# PIC16F1782 register map
Vendor: Microchip
Registers are 8-bit, read-write, reset 0x0 unless marked. A register's access mark holds for its fields unless they carry their own. Addresses are absolute, and some are shared; only a register's first bit layout is shown; [hi:lo] are bit positions; {n}, {i} and the like mark numbered series.

## SFR
0x00 INDF0 reset not defined — (power-on value xxxxxxxx)
0x01 INDF1 reset not defined — (power-on value xxxxxxxx)
0x02 PCL
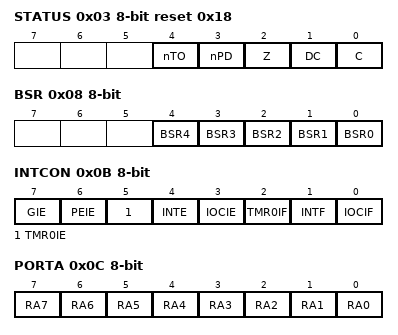
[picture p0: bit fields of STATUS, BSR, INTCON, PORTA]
0x03 STATUS reset 0x18
  [4] nTO ro, [3] nPD ro, [2] Z, [1] DC, [0] C
0x04 FSR0L
0x05 FSR0H
0x06 FSR1L
0x07 FSR1H
0x08 BSR
  [n] BSR{n} (n=0..4)
0x09 WREG
  [7:0] WREG0
0x0A PCLATH
  [6:0] PCLATH
0x0B INTCON
  [7] GIE, [6] PEIE, [5] TMR0IE, [4] INTE, [3] IOCIE, [2] TMR0IF, [1] INTF, [0] IOCIF ro
0x0C PORTA reset not defined — (power-on value xxxxxxxx)
  [n] RA{n} (n=0..7)
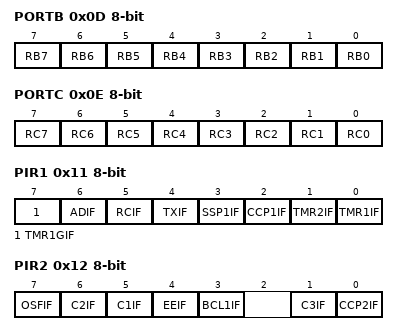
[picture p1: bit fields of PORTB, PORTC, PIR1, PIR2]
0x0D PORTB reset not defined — (power-on value xxxxxxxx)
  [n] RB{n} (n=0..7)
0x0E PORTC reset not defined — (power-on value xxxxxxxx)
  [n] RC{n} (n=0..7)
0x10 PORTE ro reset not defined — (power-on value ----x---)
  [3] RE3
0x11 PIR1
  [7] TMR1GIF — Timer1 Gate Interrupt Flag bit
  [6] ADIF — A/D Converter Interrupt Flag bit
  [5] RCIF ro — EUSART Receive Interrupt Flag bit
  [4] TXIF ro — EUSART Transmit Interrupt Flag bit
  [3] SSP1IF — Master Synchronous Serial Port (MSSP) Interrupt Flag bit
  [2] CCP1IF — CCP1 Interrupt Flag bit
  [1] TMR2IF — TMR2 to PR2 Match Interrupt Flag bit
  [0] TMR1IF — TMR1 Overflow Interrupt Flag bit
0x12 PIR2
  [7] OSFIF, [6] C2IF, [5] C1IF, [4] EEIF, [3] BCL1IF, [1] C3IF, [0] CCP2IF
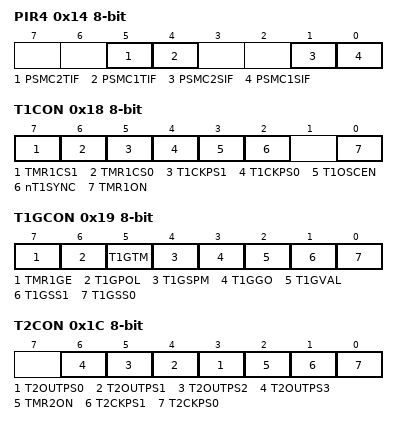
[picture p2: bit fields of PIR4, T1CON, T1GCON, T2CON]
0x14 PIR4
  [5] PSMC2TIF, [4] PSMC1TIF, [1] PSMC2SIF, [0] PSMC1SIF
0x15 TMR0 reset not defined — (power-on value xxxxxxxx)
0x16 TMR1L reset not defined — (power-on value xxxxxxxx)
0x17 TMR1H reset not defined — (power-on value xxxxxxxx)
0x18 T1CON
  [7] TMR1CS1, [6] TMR1CS0, [5] T1CKPS1, [4] T1CKPS0, [3] T1OSCEN, [2] nT1SYNC, [0] TMR1ON
0x19 T1GCON reset not defined — (power-on value 00000x00)
  [7] TMR1GE, [6] T1GPOL, [5] T1GTM, [4] T1GSPM, [3] T1GGO, [2] T1GVAL ro, [1] T1GSS1, [0] T1GSS0
0x1A TMR2
0x1B PR2 reset 0xFF
0x1C T2CON
  [n+3] T2OUTPS{n} (n=0..3), [2] TMR2ON, [1] T2CKPS1, [0] T2CKPS0
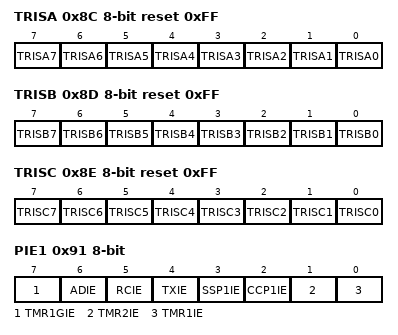
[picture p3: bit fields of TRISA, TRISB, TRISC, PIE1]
0x8C TRISA reset 0xFF — PORTA Data Direction Control Register
  [n] TRISA{n} (n=0..7)
0x8D TRISB reset 0xFF
  [n] TRISB{n} (n=0..7)
0x8E TRISC reset 0xFF — PORTB Data Direction Control Register
  [n] TRISC{n} (n=0..7)
0x90 TRISE reset 0x8
  [3] TRISE3
0x91 PIE1 — Peripheral Interrupt Enable Register 1
  [7] TMR1GIE — Timer1 Gate Interrupt Enable bit
  [6] ADIE — A/D Converter Interrupt Enable bit
  [5] RCIE — EUSART Receive Interrupt Enable bit
  [4] TXIE — EUSART Transmit Interrupt Enable bit
  [3] SSP1IE — Master Synchronous Serial Port (MSSP) Interrupt Enable bit
  [2] CCP1IE — CCP1 Interrupt Enable bit
  [1] TMR2IE — TMR2 to PR2 Match Interrupt Enable bit
  [0] TMR1IE — TMR1 Overflow Interrupt Enable bit
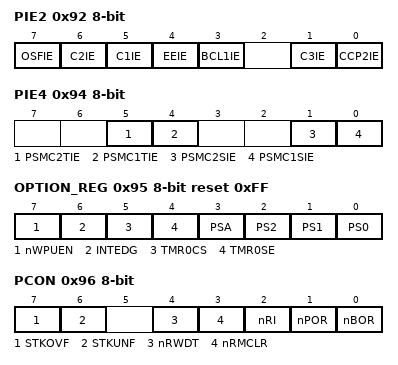
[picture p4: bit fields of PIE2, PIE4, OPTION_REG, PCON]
0x92 PIE2 — Peripheral Interrupt Enable Register 2
  [7] OSFIE — CCP2 Interrupt Enable bit
  [6] C2IE — Comparator C2 Interrupt Enable bit
  [5] C1IE — Comparator C1 Interrupt Enable bit
  [4] EEIE — EEPROM Write Completion Interrupt Enable bit
  [3] BCL1IE — MSSP Bus Collision Interrupt Interrupt Enable bit
  [1] C3IE
  [0] CCP2IE
0x94 PIE4
  [5] PSMC2TIE, [4] PSMC1TIE, [1] PSMC2SIE, [0] PSMC1SIE
0x95 OPTION_REG reset 0xFF — Option Register
  [7] nWPUEN — Weak Pull-up Enable bit
  [6] INTEDG — Interrupt Edge Select bit
  [5] TMR0CS — TMR0 Clock Source Select bit
  [4] TMR0SE — TMR0 Source Edge Select bit
  [3] PSA — Prescaler Active bit
  [2] PS2 — Prescaler Rate Select bits
  [1] PS1 — Prescaler Rate Select bits
  [0] PS0 — Prescaler Rate Select bits
0x96 PCON reset not defined — Power Control Register (power-on value 00-111qq)
  [7] STKOVF — Stack Overflow Flag bit
  [6] STKUNF — Stack Underflow Flag bit
  [4] nRWDT
  [3] nRMCLR — MCLR Reset Flag bit
  [2] nRI — RESET Instruction Flag bit
  [1] nPOR — Power-on Reset Status bit
  [0] nBOR — Brown-out Reset Status bit
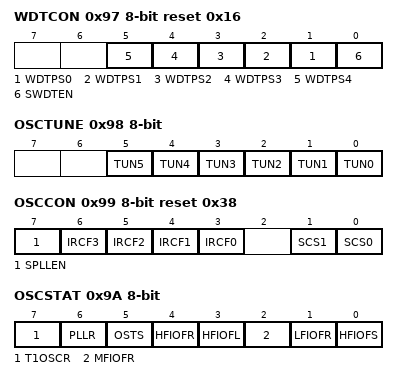
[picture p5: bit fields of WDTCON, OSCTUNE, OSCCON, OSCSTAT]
0x97 WDTCON reset 0x16 — Watchdog Timer Control Register
  [n+1] WDTPS{n} (n=0..4) — Watchdog Timer Period Select bits
  [0] SWDTEN — Software Enable/Disable for Watch Dog Timer bit
0x98 OSCTUNE — Oscillator Tuning Register
  [n] TUN{n} (n=0..5) — Frequency Tuning bits
0x99 OSCCON reset 0x38 — Oscillator Control Register
  [7] SPLLEN — Software PLL Enable bit
  [n+3] IRCF{n} (n=0..3) — Internal Oscillator Frequency Select bits
  [1] SCS1 — System clock select bit
  [0] SCS0 — System clock select bit
0x9A OSCSTAT ro reset not defined — Oscillator Status Register (power-on value 10q00q00)
  [7] T1OSCR — Timer1 Oscillator Ready bit
  [6] PLLR — 4x PLL Ready bit
  [5] OSTS — Oscillator Start-up Time-out Status bit
  [4] HFIOFR — High Freqency Internal Oscillator Ready bit
  [3] HFIOFL — High Freqency Internal Oscillator Status Locked bit
  [2] MFIOFR — Medium Freqency Internal Oscillator Ready bit
  [1] LFIOFR — Low Freqency Internal Oscillator Ready bit
  [0] HFIOFS — Low Freqency Internal Oscillator Ready bit
0x9B ADRESL reset not defined — A/D Result Register LSB (power-on value xxxxxxxx)
0x9C ADRESH reset not defined — A/D Result Register MSB (power-on value xxxxxxxx)
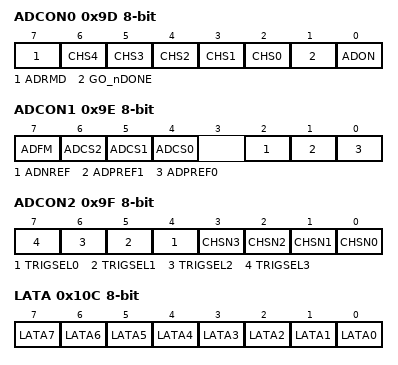
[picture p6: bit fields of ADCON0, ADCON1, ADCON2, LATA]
0x9D ADCON0 — Analog-to-Digital Control Register 0
  [7] ADRMD
  [n+2] CHS{n} (n=0..4) — Analog Channel Select bits
  [1] GO_nDONE — A/D Conversion Status bit
  [0] ADON — A/D Module Enable bit
0x9E ADCON1 — Analog-to-Digital Control Register 1
  [7] ADFM — A/D Result Format Select bit
  [6] ADCS2 — A/D Conversion Clock Select bits
  [5] ADCS1 — A/D Conversion Clock Select bits
  [4] ADCS0 — A/D Conversion Clock Select bits
  [2] ADNREF — A/D Negative Voltage Reference Configuration
  [1] ADPREF1 — A/D Positive Voltage Reference Configuration
  [0] ADPREF0 — A/D Positive Voltage Reference Configuration
0x9F ADCON2
  [n+4] TRIGSEL{n} (n=0..3), [n] CHSN{n} (n=0..3)
0x10C LATA reset not defined — (power-on value xxxxxxxx)
  [n] LATA{n} (n=0..7)
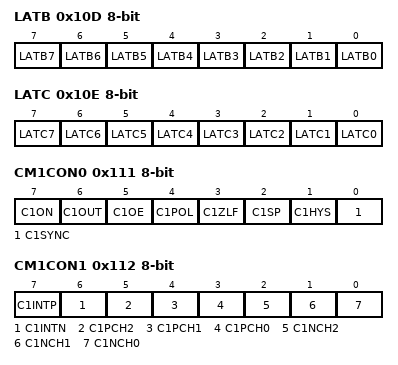
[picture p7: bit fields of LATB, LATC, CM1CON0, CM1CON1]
0x10D LATB reset not defined — (power-on value xxxxxxxx)
  [n] LATB{n} (n=0..7)
0x10E LATC reset not defined — (power-on value xxxxxxxx)
  [n] LATC{n} (n=0..7)
0x111 CM1CON0 reset not defined — (power-on value 0000x100)
  [7] C1ON — Comparator Enable bit
  [6] C1OUT ro — Comparator Output bit
  [5] C1OE — Comparator Output Enable bit
  [4] C1POL — Comparator Output Polarity Select bit
  [3] C1ZLF
  [2] C1SP — Comparator Speed/Power Select bit
  [1] C1HYS — Comparator Hysteresis Enable bit
  [0] C1SYNC — Comparator Output Synchronous Mode bit
0x112 CM1CON1
  [7] C1INTP — Comparator Interrupt on Positive going edge Enable bits
  [6] C1INTN — Comparator Interrupt on Negative going edge Enable bits
  [5] C1PCH2
  [4] C1PCH1
  [3] C1PCH0
  [2] C1NCH2
  [1] C1NCH1 — Comparator Negative Input Channel Select bits
  [0] C1NCH0 — Comparator Negative Input Channel Select bits
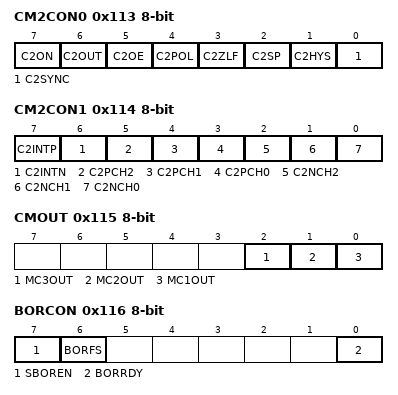
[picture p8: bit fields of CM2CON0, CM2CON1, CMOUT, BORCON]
0x113 CM2CON0 reset not defined — (power-on value 0000x100)
  [7] C2ON, [6] C2OUT ro, [5] C2OE, [4] C2POL, [3] C2ZLF, [2] C2SP, [1] C2HYS, [0] C2SYNC
0x114 CM2CON1
  [7] C2INTP — Comparator Interrupt on Positive going edge Enable bits
  [6] C2INTN — Comparator Interrupt on Negative going edge Enable bits
  [5] C2PCH2
  [4] C2PCH1
  [3] C2PCH0
  [2] C2NCH2
  [1] C2NCH1 — Comparator Negative Input Channel Select bits
  [0] C2NCH0 — Comparator Negative Input Channel Select bits
0x115 CMOUT ro — Comparator Output Register
  [2] MC3OUT, [1] MC2OUT, [0] MC1OUT
0x116 BORCON reset not defined — Brown-out Reset Control Register (power-on value 10-----q)
  [7] SBOREN — Software Brown Out Reset Enable bit
  [6] BORFS
  [0] BORRDY ro — Brown-out Reset Circuit Ready Status bit
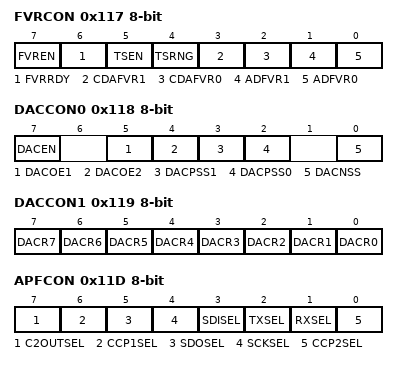
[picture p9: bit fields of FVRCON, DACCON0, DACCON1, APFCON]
0x117 FVRCON reset not defined — Fixed Voltage Reference Control Register (power-on value 0q000000)
  [7] FVREN — Fixed Voltage Reference Enable
  [6] FVRRDY ro — Fixed Voltage Reference Ready Flag
  [5] TSEN
  [4] TSRNG
  [3] CDAFVR1 — Comparator and D/A Converter Fixed Voltage Reference Selection
  [2] CDAFVR0 — Comparator and D/A Converter Fixed Voltage Reference Selection
  [1] ADFVR1 — A/D Converter Fixed Voltage Reference Selection
  [0] ADFVR0 — A/D Converter Fixed Voltage Reference Selection
0x118 DACCON0 reset not defined — Voltage Reference Control Register 0 (power-on value 0-0x00-0)
  [7] DACEN — DAC 1 Enable bit
  [5] DACOE1 — DAC1 Voltage Output Enable bit
  [4] DACOE2
  [3] DACPSS1 — DAC1 Positive Source Select bits
  [2] DACPSS0 — DAC1 Positive Source Select bits
  [0] DACNSS — DAC1 Negative Source Select bits
0x119 DACCON1 — Voltage Reference Control Register 1
  [7] DACR7
  [6] DACR6
  [5] DACR5
  [n] DACR{n} (n=0..4) — DAC1 Voltage Output Select bits
0x11D APFCON — Alternate Pin Function Control Register
  [7] C2OUTSEL, [6] CCP1SEL, [5] SDOSEL, [4] SCKSEL, [3] SDISEL, [2] TXSEL, [1] RXSEL, [0] CCP2SEL
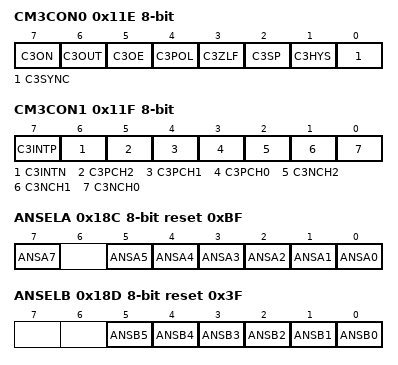
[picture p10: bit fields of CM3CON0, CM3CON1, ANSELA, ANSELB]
0x11E CM3CON0 reset not defined — (power-on value 0000x100)
  [7] C3ON, [6] C3OUT, [5] C3OE, [4] C3POL, [3] C3ZLF, [2] C3SP, [1] C3HYS, [0] C3SYNC
0x11F CM3CON1
  [7] C3INTP, [6] C3INTN, [5] C3PCH2, [4] C3PCH1, [3] C3PCH0, [2] C3NCH2, [1] C3NCH1, [0] C3NCH0
0x18C ANSELA reset 0xBF
  [7] ANSA7, [n] ANSA{n} (n=0..5)
0x18D ANSELB reset 0x3F
  [n] ANSB{n} (n=0..5)
0x191 EEADRL
0x192 EEADRH reset 0x80
  [6:0] EEADRH
0x193 EEDATL reset not defined — (power-on value xxxxxxxx)
0x194 EEDATH reset not defined — (power-on value --xxxxxx)
  [5:0] EEDATH
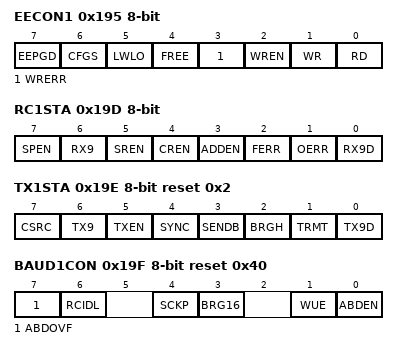
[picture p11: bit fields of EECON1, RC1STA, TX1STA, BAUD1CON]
0x195 EECON1 reset not defined — (power-on value 0000x000)
  [7] EEPGD — FLASH Program / Data EEPROM Memory Select bit
  [6] CFGS — FLASH Program / Data EEPROM or Configuration Select bit
  [5] LWLO — Load Write Latches Only bit
  [4] FREE — Program FLASH Erase Enable bit
  [3] WRERR — Sequence Error Flag bit
  [2] WREN — Program/Erase Enable bit
  [1] WR — Write Control bit (can only be set)
  [0] RD — Read Control bit (can only be set)
0x196 EECON2 wo
0x197 VREGCON reset 0x1
  [1] VREGPM
0x199 RC1REG ro
0x19A TX1REG
0x19B SP1BRGL
0x19C SP1BRGH
0x19D RC1STA
  [7] SPEN, [6] RX9, [5] SREN, [4] CREN, [3] ADDEN, [2] FERR ro, [1] OERR ro, [0] RX9D ro
0x19E TX1STA reset 0x2
  [7] CSRC, [6] TX9, [5] TXEN, [4] SYNC, [3] SENDB, [2] BRGH, [1] TRMT ro, [0] TX9D
0x19F BAUD1CON reset 0x40
  [7] ABDOVF ro, [6] RCIDL ro, [4] SCKP, [3] BRG16, [1] WUE, [0] ABDEN
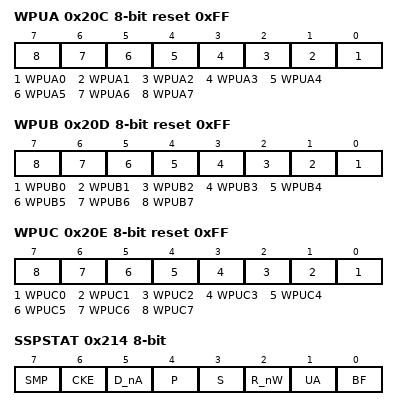
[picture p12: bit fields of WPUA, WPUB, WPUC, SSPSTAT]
0x20C WPUA reset 0xFF
  [n] WPUA{n} (n=0..7)
0x20D WPUB reset 0xFF
  [n] WPUB{n} (n=0..7)
0x20E WPUC reset 0xFF
  [n] WPUC{n} (n=0..7)
0x210 WPUE reset 0x8
  [3] WPUE3
0x211 SSPBUF reset not defined — (power-on value xxxxxxxx)
0x212 SSPADD
0x213 SSPMSK reset 0xFF
0x214 SSPSTAT
  [7] SMP, [6] CKE, [5] D_nA, [4] P, [3] S, [2] R_nW, [1] UA, [0] BF
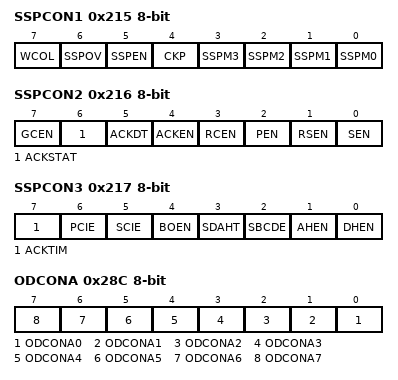
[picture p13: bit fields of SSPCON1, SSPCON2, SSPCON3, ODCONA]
0x215 SSPCON1
  [7] WCOL, [6] SSPOV, [5] SSPEN, [4] CKP, [n] SSPM{n} (n=0..3)
0x216 SSPCON2
  [7] GCEN, [6] ACKSTAT, [5] ACKDT, [4] ACKEN, [3] RCEN, [2] PEN, [1] RSEN, [0] SEN
0x217 SSPCON3
  [7] ACKTIM, [6] PCIE, [5] SCIE, [4] BOEN, [3] SDAHT, [2] SBCDE, [1] AHEN, [0] DHEN
0x28C ODCONA
  [n] ODCONA{n} (n=0..7)
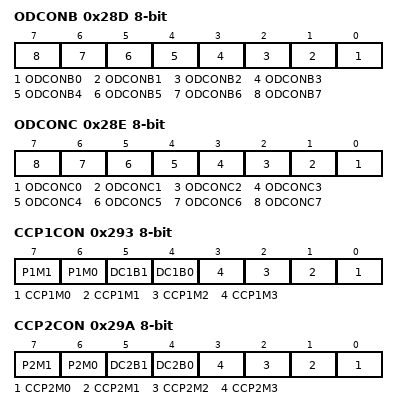
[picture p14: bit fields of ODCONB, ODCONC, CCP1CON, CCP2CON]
0x28D ODCONB
  [n] ODCONB{n} (n=0..7)
0x28E ODCONC
  [n] ODCONC{n} (n=0..7)
0x291 CCPR1L reset not defined — (power-on value xxxxxxxx)
0x292 CCPR1H reset not defined — (power-on value xxxxxxxx)
0x293 CCP1CON
  [7] P1M1, [6] P1M0, [5] DC1B1, [4] DC1B0, [n] CCP1M{n} (n=0..3)
0x298 CCPR2L reset not defined — (power-on value xxxxxxxx)
0x299 CCPR2H reset not defined — (power-on value xxxxxxxx)
0x29A CCP2CON
  [7] P2M1, [6] P2M0, [5] DC2B1, [4] DC2B0, [n] CCP2M{n} (n=0..3)
0x30C SLRCONA
  [n] SLRCONA{n} (n=0..7)
0x30D SLRCONB
  [n] SLRCONB{n} (n=0..7)
0x30E SLRCONC
  [n] SLRCONC{n} (n=0..7)
0x38C INLVLA
  [n] INLVLA{n} (n=0..7)
0x38D INLVLB
  [n] INLVLB{n} (n=0..7)
0x38E INLVLC reset 0xFF
  [n] INLVLC{n} (n=0..7)
0x390 INLVLE reset 0x8
  [3] INLVLE3
0x391 IOCAP — Interrupt-On-Change Positive Edge Register
  [n] IOCAP{n} (n=0..7)
0x392 IOCAN — Interrupt-On-Change Negative Edge Register
  [n] IOCAN{n} (n=0..7)
0x393 IOCAF — Interrupt-On-Change Flag Register
  [n] IOCAF{n} (n=0..7)
0x394 IOCBP — Interrupt-On-Change Positive Edge Register
  [n] IOCBP{n} (n=0..7)
0x395 IOCBN — Interrupt-On-Change Negative Edge Register
  [n] IOCBN{n} (n=0..7)
0x396 IOCBF — Interrupt-On-Change Flag Register
  [n] IOCBF{n} (n=0..7)
0x397 IOCCP
  [n] IOCCP{n} (n=0..7)
0x398 IOCCN
  [n] IOCCN{n} (n=0..7)
0x399 IOCCF
  [n] IOCCF{n} (n=0..7)
0x39D IOCEP
  [3] IOCEP3
0x39E IOCEN
  [3] IOCEN3
0x39F IOCEF
  [3] IOCEF3
0x511 OPA1CON
  [7] OPA1EN, [6] OPA1SP, [1] OPA1CH1, [0] OPA1CH0
0x513 OPA2CON
  [7] OPA2EN, [6] OPA2SP, [1] OPA2CH1, [0] OPA2CH0
0x51A CLKRCON reset 0x30
  [7] CLKREN, [6] CLKROE, [5] CLKRSLR, [4] CLKRDC1, [3] CLKRDC0, [2] CLKRDIV2, [1] CLKRDIV1, [0] CLKRDIV0
0x811 PSMC1CON
  [7] PSMC1EN, [6] PSMC1LD, [5] P1DBFE, [4] P1DBRE, [3:0] P1MODE
0x812 PSMC1MDL
  [7] P1MDLEN, [6] P1MDLPOL, [5] P1MDLBIT, [3:0] P1MSRC
0x813 PSMC1SYNC
  [1] P1SYNC1, [0] P1SYNC0
0x814 PSMC1CLK
  [5] P1CPRE1, [4] P1CPRE0, [1] P1CSRC1, [0] P1CSRC0
0x815 PSMC1OEN
  [5] P1OEF, [4] P1OEE, [3] P1OED, [2] P1OEC, [1] P1OEB, [0] P1OEA
0x816 PSMC1POL
  [6] P1INPOL, [5] P1POLF, [4] P1POLE, [3] P1POLD, [2] P1POLC, [1] P1POLB, [0] P1POLA
0x817 PSMC1BLNK
  [5:4] P1FEBM, [1:0] P1REBM
0x818 PSMC1REBS
  [7] P1REBSIN, [3] P1REBSC3, [2] P1REBSC2, [1] P1REBSC1
0x819 PSMC1FEBS
  [7] P1FEBSIN, [3] P1FEBSC3, [2] P1FEBSC2, [1] P1FEBSC1
0x81A PSMC1PHS
  [7] P1PHSIN, [3] P1PHSC3, [2] P1PHSC2, [1] P1PHSC1, [0] P1PHST
0x81B PSMC1DCS
  [7] P1DCSIN, [3] P1DCSC3, [2] P1DCSC2, [1] P1DCSC1, [0] P1DCST
0x81C PSMC1PRS
  [7] P1PRSIN, [3] P1PRSC3, [2] P1PRSC2, [1] P1PRSC1, [0] P1PRST
0x81D PSMC1ASDC
  [7] P1ASE, [6] P1ASDEN, [5] P1ARSEN, [0] P1ASDOV
0x81E PSMC1ASDL
  [5] P1ASDLF, [4] P1ASDLE, [3] P1ASDLD, [2] P1ASDLC, [1] P1ASDLB, [0] P1ASDLA
0x81F PSMC1ASDS
  [7] P1ASDSIN, [3] P1ASDSC3, [2] P1ASDSC2, [1] P1ASDSC1
0x820 PSMC1INT
  [7] P1TOVIE, [6] P1TPHIE, [5] P1TDCIE, [4] P1TPRIE, [3] P1TOVIF, [2] P1TPHIF, [1] P1TDCIF, [0] P1TPRIF
0x821 PSMC1PHL
  [n] PSMC1PH{n} (n=0..7)
0x822 PSMC1PHH
  [n-8] PSMC1PH{n} (n=8..15)
0x823 PSMC1DCL
  [n] PSMC1DC{n} (n=0..7)
0x824 PSMC1DCH
  [n-8] PSMC1DC{n} (n=8..15)
0x825 PSMC1PRL
  [n] PSMC1PR{n} (n=0..7)
0x826 PSMC1PRH
  [n-8] PSMC1PR{n} (n=8..15)
0x827 PSMC1TMRL reset 0x1
  [n] PSMC1TMR{n} (n=0..7)
0x828 PSMC1TMRH
  [n-8] PSMC1TMR{n} (n=8..15)
0x829 PSMC1DBR
  [n] PSMC1DBR{n} (n=0..7)
0x82A PSMC1DBF
  [n] PSMC1DBF{n} (n=0..7)
0x82B PSMC1BLKR
  [n] PSMC1BLKR{n} (n=0..7)
0x82C PSMC1BLKF
  [n] PSMC1BLKF{n} (n=0..7)
0x82D PSMC1FFA
  [n] PSMC1FFA{n} (n=0..3)
0x82E PSMC1STR0 reset 0x1
  [5] P1STRF, [4] P1STRE, [3] P1STRD, [2] P1STRC, [1] P1STRB, [0] P1STRA
0x82F PSMC1STR1
  [7] P1SSYNC, [1] P1LSMEN, [0] P1HSMEN
0x831 PSMC2CON
  [7] PSMC2EN, [6] PSMC2LD, [5] P2DBFE, [4] P2DBRE, [3:0] P2MODE
0x832 PSMC2MDL
  [7] P2MDLEN, [6] P2MDLPOL, [5] P2MDLBIT, [3:0] P2MSRC
0x833 PSMC2SYNC
  [1] P2SYNC1, [0] P2SYNC0
0x834 PSMC2CLK
  [5] P2CPRE1, [4] P2CPRE0, [1] P2CSRC1, [0] P2CSRC0
0x835 PSMC2OEN
  [1] P2OEB, [0] P2OEA
0x836 PSMC2POL
  [6] P2INPOL, [1] P2POLB, [0] P2POLA
0x837 PSMC2BLNK
  [5:4] P2FEBM, [1:0] P2REBM
0x838 PSMC2REBS
  [7] P2REBSIN, [3] P2REBSC3, [2] P2REBSC2, [1] P2REBSC1
0x839 PSMC2FEBS
  [7] P2FEBSIN, [3] P2FEBSC3, [2] P2FEBSC2, [1] P2FEBSC1
0x83A PSMC2PHS
  [7] P2PHSIN, [3] P2PHSC3, [2] P2PHSC2, [1] P2PHSC1, [0] P2PHST
0x83B PSMC2DCS
  [7] P2DCSIN, [3] P2DCSC3, [2] P2DCSC2, [1] P2DCSC1, [0] P2DCST
0x83C PSMC2PRS
  [7] P2PRSIN, [3] P2PRSC3, [2] P2PRSC2, [1] P2PRSC1, [0] P2PRST
0x83D PSMC2ASDC
  [7] P2ASE, [6] P2ASDEN, [5] P2ARSEN, [0] P2ASDOV
0x83E PSMC2ASDL
  [1] P2ASDLB, [0] P2ASDLA
0x83F PSMC2ASDS
  [7] P2ASDSIN, [3] P2ASDSC3, [2] P2ASDSC2, [1] P2ASDSC1
0x840 PSMC2INT
  [7] P2TOVIE, [6] P2TPHIE, [5] P2TDCIE, [4] P2TPRIE, [3] P2TOVIF, [2] P2TPHIF, [1] P2TDCIF, [0] P2TPRIF
0x841 PSMC2PHL
  [n] PSMC2PH{n} (n=0..7)
0x842 PSMC2PHH
  [n-8] PSMC2PH{n} (n=8..15)
0x843 PSMC2DCL
  [n] PSMC2DC{n} (n=0..7)
0x844 PSMC2DCH
  [n-8] PSMC2DC{n} (n=8..15)
0x845 PSMC2PRL
  [n] PSMC2PR{n} (n=0..7)
0x846 PSMC2PRH
  [n-8] PSMC2PR{n} (n=8..15)
0x847 PSMC2TMRL reset 0x1
  [n] PSMC2TMR{n} (n=0..7)
0x848 PSMC2TMRH
  [n-8] PSMC2TMR{n} (n=8..15)
0x849 PSMC2DBR
  [n] PSMC2DBR{n} (n=0..7)
0x84A PSMC2DBF
  [n] PSMC2DBF{n} (n=0..7)
0x84B PSMC2BLKR
  [n] PSMC2BLKR{n} (n=0..7)
0x84C PSMC2BLKF
  [n] PSMC2BLKF{n} (n=0..7)
0x84D PSMC2FFA
  [n] PSMC2FFA{n} (n=0..3)
0x84E PSMC2STR0 reset 0x1
  [1] P2STRB, [0] P2STRA
0x84F PSMC2STR1
  [7] P2SSYNC, [1] P2LSMEN, [0] P2HSMEN
0xFE4 STATUS_SHAD reset not defined — (power-on value -----xxx)
  [2] Z_SHAD, [1] DC_SHAD, [0] C_SHAD
0xFE5 WREG_SHAD reset not defined — (power-on value xxxxxxxx)
0xFE6 BSR_SHAD reset not defined — (power-on value ---xxxxx)
  [4:0] BSR_SHAD
0xFE7 PCLATH_SHAD reset not defined — (power-on value -xxxxxxx)
  [6:0] PCLATH_SHAD
0xFE8 FSR0L_SHAD reset not defined — (power-on value xxxxxxxx)
0xFE9 FSR0H_SHAD reset not defined — (power-on value xxxxxxxx)
0xFEA FSR1L_SHAD reset not defined — (power-on value xxxxxxxx)
0xFEB FSR1H_SHAD reset not defined — (power-on value xxxxxxxx)
0xFED STKPTR reset 0x1F — Current Stack pointer
  [4:0] STKPTR
0xFEE TOSL reset not defined — Top of Stack Low byte (power-on value xxxxxxxx)
0xFEF TOSH reset not defined — Top of Stack High byte (power-on value -xxxxxxx)
  [6:0] TOSH
